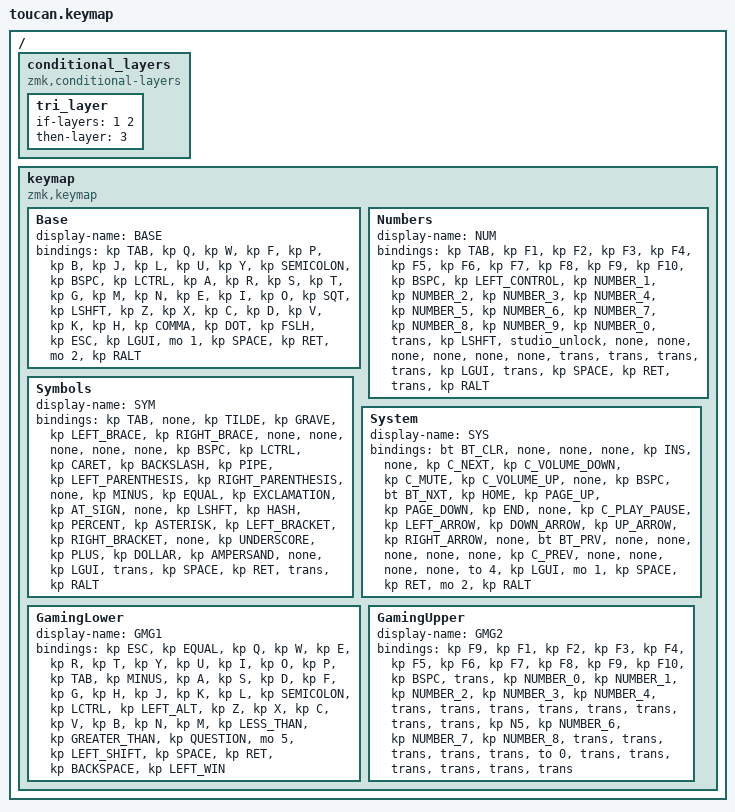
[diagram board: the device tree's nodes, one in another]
#include <behaviors.dtsi>
#include <dt-bindings/zmk/bt.h>
#include <dt-bindings/zmk/keys.h>

#define BASE 0
#define NAV  1
#define SYM  2
#define ADJ  3

/ {
    conditional_layers {
        compatible = "zmk,conditional-layers";

        tri_layer {
            if-layers = <1 2>;
            then-layer = <3>;
        };
    };

    keymap {
        compatible = "zmk,keymap";

        Base {
            display-name = "BASE";
            bindings = <
&kp TAB  &kp Q  &kp W  &kp F  &kp P  &kp B  &kp J  &kp L  &kp U  &kp Y  &kp SEMICOLON  &kp BSPC  &kp LCTRL  &kp A  &kp R  &kp S  &kp T  &kp G  &kp M  &kp N  &kp E  &kp I  &kp O  &kp SQT  &kp LSHFT  &kp Z  &kp X  &kp C  &kp D  &kp V  &kp K  &kp H  &kp COMMA  &kp DOT  &kp FSLH  &kp ESC  &kp LGUI  &mo 1  &kp SPACE  &kp RET  &mo 2  &kp RALT
            >;
        };

        Numbers {
            display-name = "NUM";
            bindings = <
&kp TAB  &kp F1  &kp F2  &kp F3  &kp F4  &kp F5  &kp F6  &kp F7  &kp F8  &kp F9  &kp F10  &kp BSPC  &kp LEFT_CONTROL  &kp NUMBER_1  &kp NUMBER_2  &kp NUMBER_3  &kp NUMBER_4  &kp NUMBER_5  &kp NUMBER_6  &kp NUMBER_7  &kp NUMBER_8  &kp NUMBER_9  &kp NUMBER_0  &trans  &kp LSHFT  &studio_unlock  &none  &none  &none  &none  &none  &none  &trans  &trans  &trans  &trans  &kp LGUI  &trans  &kp SPACE  &kp RET  &trans  &kp RALT
            >;
        };

        Symbols {
            display-name = "SYM";
            bindings = <
&kp TAB  &none  &kp TILDE  &kp GRAVE  &kp LEFT_BRACE  &kp RIGHT_BRACE  &none  &none  &none  &none  &none  &kp BSPC  &kp LCTRL  &kp CARET  &kp BACKSLASH  &kp PIPE  &kp LEFT_PARENTHESIS  &kp RIGHT_PARENTHESIS  &none  &kp MINUS  &kp EQUAL  &kp EXCLAMATION  &kp AT_SIGN  &none  &kp LSHFT  &kp HASH  &kp PERCENT  &kp ASTERISK  &kp LEFT_BRACKET  &kp RIGHT_BRACKET  &none  &kp UNDERSCORE  &kp PLUS  &kp DOLLAR  &kp AMPERSAND  &none  &kp LGUI  &trans  &kp SPACE  &kp RET  &trans  &kp RALT
            >;
        };

        System {
            display-name = "SYS";
            bindings = <
&bt BT_CLR  &none  &none  &none  &kp INS  &none  &kp C_NEXT  &kp C_VOLUME_DOWN  &kp C_MUTE  &kp C_VOLUME_UP  &none  &kp BSPC  &bt BT_NXT  &kp HOME  &kp PAGE_UP  &kp PAGE_DOWN  &kp END  &none  &kp C_PLAY_PAUSE  &kp LEFT_ARROW  &kp DOWN_ARROW  &kp UP_ARROW  &kp RIGHT_ARROW  &none  &bt BT_PRV  &none  &none  &none  &none  &none  &kp C_PREV  &none  &none  &none  &none  &to 4  &kp LGUI  &mo 1  &kp SPACE  &kp RET  &mo 2  &kp RALT
            >;
        };

        GamingLower {
            display-name = "GMG1";
            bindings = <
&kp ESC  &kp EQUAL  &kp Q  &kp W  &kp E  &kp R  &kp T  &kp Y  &kp U  &kp I  &kp O  &kp P  &kp TAB  &kp MINUS  &kp A  &kp S  &kp D  &kp F  &kp G  &kp H  &kp J  &kp K  &kp L  &kp SEMICOLON  &kp LCTRL  &kp LEFT_ALT  &kp Z  &kp X  &kp C  &kp V  &kp B  &kp N  &kp M  &kp LESS_THAN  &kp GREATER_THAN  &kp QUESTION  &mo 5  &kp LEFT_SHIFT  &kp SPACE  &kp RET  &kp BACKSPACE  &kp LEFT_WIN
            >;
        };

        GamingUpper {
            display-name = "GMG2";
            bindings = <
&kp F9  &kp F1  &kp F2  &kp F3  &kp F4  &kp F5  &kp F6  &kp F7  &kp F8  &kp F9  &kp F10  &kp BSPC  &trans  &kp NUMBER_0  &kp NUMBER_1  &kp NUMBER_2  &kp NUMBER_3  &kp NUMBER_4  &trans  &trans  &trans  &trans  &trans  &trans  &trans  &trans  &kp N5  &kp NUMBER_6  &kp NUMBER_7  &kp NUMBER_8  &trans  &trans  &trans  &trans  &trans  &to 0  &trans  &trans  &trans  &trans  &trans  &trans
            >;
        };
    };
};
